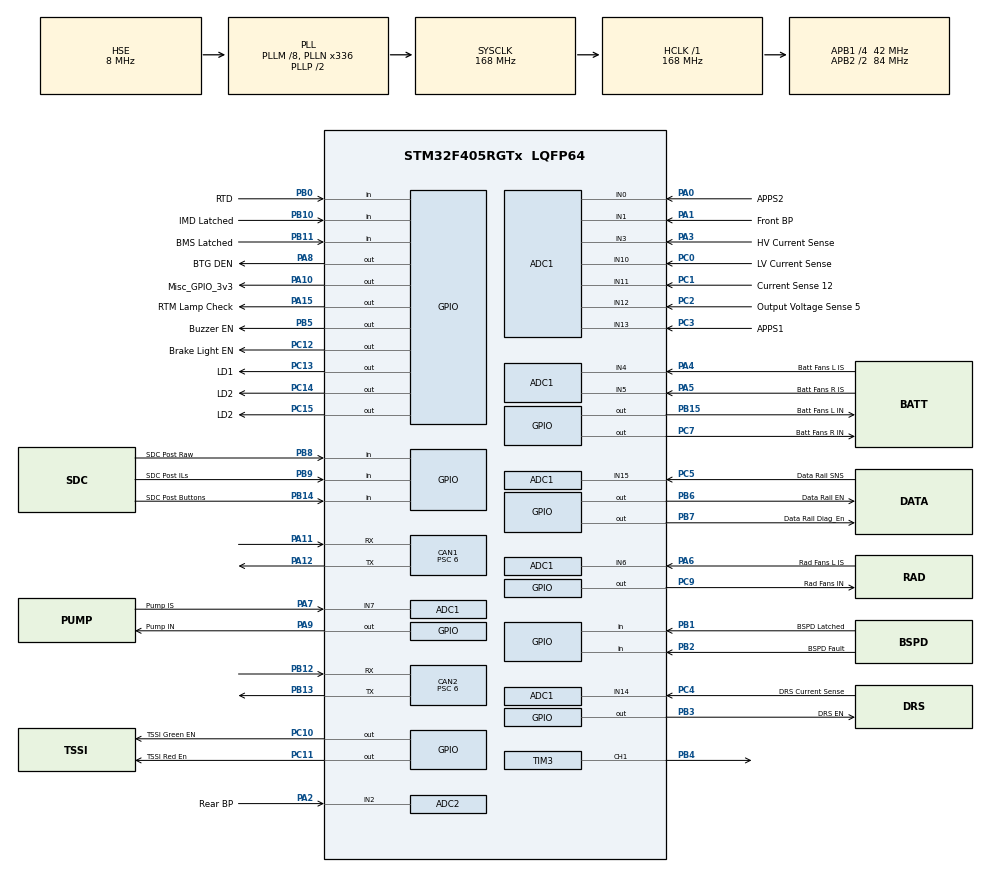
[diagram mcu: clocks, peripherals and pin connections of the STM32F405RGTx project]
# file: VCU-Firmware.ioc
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ADC1.Channel-0\#ChannelRegularConversion=ADC_CHANNEL_0
ADC1.ClockPrescaler=ADC_CLOCK_SYNC_PCLK_DIV6
ADC1.NbrOfConversionFlag=1
ADC1.Rank-0\#ChannelRegularConversion=1
ADC1.SamplingTime-0\#ChannelRegularConversion=ADC_SAMPLETIME_3CYCLES
ADC1.master=1
ADC2.Channel-0\#ChannelRegularConversion=ADC_CHANNEL_2
ADC2.ClockPrescaler=ADC_CLOCK_SYNC_PCLK_DIV6
ADC2.NbrOfConversionFlag=1
ADC2.Rank-0\#ChannelRegularConversion=1
ADC2.SamplingTime-0\#ChannelRegularConversion=ADC_SAMPLETIME_3CYCLES
CAN1.ABOM=ENABLE
CAN1.BS1=CAN_BS1_11TQ
CAN1.BS2=CAN_BS2_2TQ
CAN1.CalculateBaudRate=500000
CAN1.CalculateTimeBit=2000
CAN1.CalculateTimeQuantum=142.85714285714286
CAN1.Mode=CAN_MODE_NORMAL
CAN1.NART=ENABLE
CAN1.Prescaler=6
CAN2.ABOM=ENABLE
CAN2.BS1=CAN_BS1_11TQ
CAN2.BS2=CAN_BS2_2TQ
CAN2.CalculateBaudRate=500000
CAN2.CalculateTimeBit=2000
CAN2.CalculateTimeQuantum=142.85714285714286
CAN2.Mode=CAN_MODE_NORMAL
CAN2.NART=ENABLE
CAN2.Prescaler=6
FREERTOS.Tasks01=defaultTask,24,128,StartDefaultTask,Default,NULL,Dynamic,NULL,NULL;IOManager,24,128,IO_Manager_Task,As external,NULL,Static,IOManagerBuffer,IOManagerControlBlock;CTRLCANManager,24,128,CTRL_CAN_Manager_Task,As external,NULL,Static,CANManagerBuffer,CANManagerControlBlock;DAQCANManager,24,128,DAQ_CAN_Manager_Task,As external,NULL,Static,DAQCANManagerBuffer,DAQCANManagerControlBlock;ConfigManager,8,128,Config_Manager_Task,As external,NULL,Static,ConfigManagerBuffer,ConfigManagerControlBlock
Mcu.Family=STM32F4
Mcu.Name=STM32F405RGTx
Mcu.Package=LQFP64
NVIC.CAN1_RX0_IRQn=true\:5\:0\:false\:false\:true\:true\:true\:true\:true
NVIC.CAN1_RX1_IRQn=true\:5\:0\:false\:false\:true\:true\:true\:true\:true
NVIC.CAN2_RX0_IRQn=true\:5\:0\:false\:false\:true\:true\:true\:true\:true
NVIC.CAN2_RX1_IRQn=true\:5\:0\:false\:false\:true\:true\:true\:true\:true
NVIC.PriorityGroup=NVIC_PRIORITYGROUP_4
NVIC.TIM1_UP_TIM10_IRQn=true\:15\:0\:false\:false\:true\:false\:false\:true\:true
NVIC.TimeBase=TIM1_UP_TIM10_IRQn
NVIC.TimeBaseIP=TIM10
PA0-WKUP.GPIO_Label=APPS2
PA0-WKUP.Signal=ADCx_IN0
PA1.GPIO_Label=Front BP
PA1.Signal=ADCx_IN1
PA10.GPIO_Label=Misc_GPIO_3v3
PA10.Signal=GPIO_Output
PA11.Mode=CAN_Activate
PA11.Signal=CAN1_RX
PA12.Mode=CAN_Activate
PA12.Signal=CAN1_TX
PA15.GPIO_Label=RTM Lamp Check
PA15.Signal=GPIO_Output
PA2.GPIO_Label=Rear BP
PA2.Signal=ADCx_IN2
PA3.GPIO_Label=HV Current Sense
PA3.Signal=ADCx_IN3
PA4.GPIO_Label=Batt Fans L IS
PA4.Signal=ADCx_IN4
PA5.GPIO_Label=Batt Fans R IS
PA5.Signal=ADCx_IN5
PA6.GPIO_Label=Rad Fans L IS
PA6.Signal=ADCx_IN6
PA7.GPIO_Label=Pump IS
PA7.Signal=ADCx_IN7
PA8.GPIO_Label=BTG DEN
PA8.Signal=GPIO_Output
PA9.GPIO_Label=Pump IN
PA9.Signal=GPIO_Output
PB0.GPIO_Label=RTD
PB0.GPIO_PuPd=GPIO_PULLUP
PB0.Signal=GPIO_Input
PB1.GPIO_Label=BSPD Latched
PB1.GPIO_PuPd=GPIO_PULLUP
PB1.Signal=GPIO_Input
PB10.GPIO_Label=IMD Latched
PB10.GPIO_PuPd=GPIO_PULLUP
PB10.Signal=GPIO_Input
PB11.GPIO_Label=BMS Latched
PB11.GPIO_PuPd=GPIO_PULLUP
PB11.Signal=GPIO_Input
PB12.Mode=CAN_Activate
PB12.Signal=CAN2_RX
PB13.Mode=CAN_Activate
PB13.Signal=CAN2_TX
PB14.GPIO_Label=SDC Post Buttons
PB14.GPIO_PuPd=GPIO_PULLUP
PB14.Signal=GPIO_Input
PB15.GPIO_Label=Batt Fans L IN
PB15.Signal=GPIO_Output
PB2.GPIO_Label=BSPD Fault
PB2.GPIO_PuPd=GPIO_PULLUP
PB2.Signal=GPIO_Input
PB3.GPIO_Label=DRS EN
PB3.Signal=GPIO_Output
PB4.Signal=S_TIM3_CH1
PB5.GPIO_Label=Buzzer EN
PB5.Signal=GPIO_Output
PB6.GPIO_Label=Data Rail EN
PB6.Signal=GPIO_Output
PB7.GPIO_Label=Data Rail Diag_En
PB7.Signal=GPIO_Output
PB8.GPIO_Label=SDC Post Raw
PB8.GPIO_PuPd=GPIO_PULLUP
PB8.Signal=GPIO_Input
PB9.GPIO_Label=SDC Post ILs
PB9.GPIO_PuPd=GPIO_PULLUP
PB9.Signal=GPIO_Input
PC0.GPIO_Label=LV Current Sense
PC0.Signal=ADCx_IN10
PC1.GPIO_Label=Current Sense 12
PC1.Signal=ADCx_IN11
PC10.GPIO_Label=TSSI Green EN
PC10.Signal=GPIO_Output
PC11.GPIO_Label=TSSI Red En
PC11.Signal=GPIO_Output
PC12.GPIO_Label=Brake Light EN
PC12.Signal=GPIO_Output
PC13-ANTI_TAMP.GPIO_Label=LD1
PC13-ANTI_TAMP.Signal=GPIO_Output
PC14-OSC32_IN.GPIO_Label=LD2
PC14-OSC32_IN.GPIO_ModeDefaultOutputPP=GPIO_MODE_OUTPUT_OD
PC14-OSC32_IN.GPIO_PuPd=GPIO_NOPULL
PC14-OSC32_IN.Signal=GPIO_Output
PC15-OSC32_OUT.GPIO_Label=LD2
PC15-OSC32_OUT.Signal=GPIO_Output
PC2.GPIO_Label=Output Voltage Sense 5
PC2.Signal=ADCx_IN12
PC3.GPIO_Label=APPS1
PC3.Signal=ADCx_IN13
PC4.GPIO_Label=DRS Current Sense
PC4.Signal=ADCx_IN14
PC5.GPIO_Label=Data Rail SNS
PC5.Signal=ADCx_IN15
PC7.GPIO_Label=Batt Fans R IN
PC7.Signal=GPIO_Output
PC9.GPIO_Label=Rad Fans IN
PC9.Signal=GPIO_Output
PH0-OSC_IN.Mode=HSE-External-Oscillator
PH0-OSC_IN.Signal=RCC_OSC_IN
PH1-OSC_OUT.Mode=HSE-External-Oscillator
PH1-OSC_OUT.Signal=RCC_OSC_OUT
ProjectManager.HeapSize=0x200
ProjectManager.StackSize=0x400
ProjectManager.TargetToolchain=Makefile
RCC.48MHZClocksFreq_Value=84000000
RCC.AHBFreq_Value=168000000
RCC.APB1CLKDivider=RCC_HCLK_DIV4
RCC.APB1Freq_Value=42000000
RCC.APB1TimFreq_Value=84000000
RCC.APB2CLKDivider=RCC_HCLK_DIV2
RCC.APB2Freq_Value=84000000
RCC.APB2TimFreq_Value=168000000
RCC.CortexFreq_Value=168000000
RCC.HCLKFreq_Value=168000000
RCC.HSE_VALUE=8000000
RCC.HSI_VALUE=16000000
RCC.LSE_VALUE=32768
RCC.PLLM=8
RCC.PLLN=336
RCC.PLLSourceVirtual=RCC_PLLSOURCE_HSE
RCC.SYSCLKFreq_VALUE=168000000
RCC.SYSCLKSource=RCC_SYSCLKSOURCE_PLLCLK
RCC.VCOOutputFreq_Value=336000000
SH.ADCx_IN0.0=ADC1_IN0,IN0
SH.ADCx_IN1.0=ADC1_IN1,IN1
SH.ADCx_IN10.0=ADC1_IN10,IN10
SH.ADCx_IN11.0=ADC1_IN11,IN11
SH.ADCx_IN12.0=ADC1_IN12,IN12
SH.ADCx_IN13.0=ADC1_IN13,IN13
SH.ADCx_IN14.0=ADC1_IN14,IN14
SH.ADCx_IN15.0=ADC1_IN15,IN15
SH.ADCx_IN2.0=ADC2_IN2,IN2
SH.ADCx_IN3.0=ADC1_IN3,IN3
SH.ADCx_IN4.0=ADC1_IN4,IN4
SH.ADCx_IN5.0=ADC1_IN5,IN5
SH.ADCx_IN6.0=ADC1_IN6,IN6
SH.ADCx_IN7.0=ADC1_IN7,IN7
SH.S_TIM3_CH1.0=TIM3_CH1,PWM Generation1 CH1
TIM3.AutoReloadPreload=TIM_AUTORELOAD_PRELOAD_ENABLE
TIM3.Channel-PWM\ Generation1\ CH1=TIM_CHANNEL_1
TIM3.Period=8399
VP_FREERTOS_VS_CMSIS_V2.Mode=CMSIS_V2
VP_SYS_VS_tim10.Mode=TIM10
VP_TIM3_VS_ClockSourceINT.Mode=Internal
board=custom

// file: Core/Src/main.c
/* USER CODE BEGIN Header */
/**
  ******************************************************************************
  * @file           : main.c
  * @brief          : Main program body
  ******************************************************************************
  * @attention
  *
  * Copyright (c) 2026 STMicroelectronics.
  * All rights reserved.
  *
  * This software is licensed under terms that can be found in the LICENSE file
  * in the root directory of this software component.
  * If no LICENSE file comes with this software, it is provided AS-IS.
  *
  ******************************************************************************
  */
/* USER CODE END Header */
#include "main.h"
#include "cmsis_os.h"

/* USER CODE BEGIN Includes */

#include <string.h>
#include "managers/can_manager.h"
#include "managers/config_manager.h"
#include "managers/io_manager.h"

/* USER CODE END Includes */

typedef StaticTask_t osStaticThreadDef_t;

ADC_HandleTypeDef hadc1;
ADC_HandleTypeDef hadc2;

CAN_HandleTypeDef hcan1;
CAN_HandleTypeDef hcan2;

TIM_HandleTypeDef htim3;

/* Definitions for defaultTask */
osThreadId_t defaultTaskHandle;
const osThreadAttr_t defaultTask_attributes = {
  .name = "defaultTask",
  .stack_size = 128 * 4,
  .priority = (osPriority_t) osPriorityNormal,
};
/* Definitions for IOManager */
osThreadId_t IOManagerHandle;
uint32_t IOManagerBuffer[ 128 ];
osStaticThreadDef_t IOManagerControlBlock;
const osThreadAttr_t IOManager_attributes = {
  .name = "IOManager",
  .cb_mem = &IOManagerControlBlock,
  .cb_size = sizeof(IOManagerControlBlock),
  .stack_mem = &IOManagerBuffer[0],
  .stack_size = sizeof(IOManagerBuffer),
  .priority = (osPriority_t) osPriorityNormal,
};
/* Definitions for CTRLCANManager */
osThreadId_t CTRLCANManagerHandle;
uint32_t CANManagerBuffer[ 128 ];
osStaticThreadDef_t CANManagerControlBlock;
const osThreadAttr_t CTRLCANManager_attributes = {
  .name = "CTRLCANManager",
  .cb_mem = &CANManagerControlBlock,
  .cb_size = sizeof(CANManagerControlBlock),
  .stack_mem = &CANManagerBuffer[0],
  .stack_size = sizeof(CANManagerBuffer),
  .priority = (osPriority_t) osPriorityNormal,
};
/* Definitions for DAQCANManager */
osThreadId_t DAQCANManagerHandle;
uint32_t DAQCANManagerBuffer[ 128 ];
osStaticThreadDef_t DAQCANManagerControlBlock;
const osThreadAttr_t DAQCANManager_attributes = {
  .name = "DAQCANManager",
  .cb_mem = &DAQCANManagerControlBlock,
  .cb_size = sizeof(DAQCANManagerControlBlock),
  .stack_mem = &DAQCANManagerBuffer[0],
  .stack_size = sizeof(DAQCANManagerBuffer),
  .priority = (osPriority_t) osPriorityNormal,
};
/* Definitions for ConfigManager */
osThreadId_t ConfigManagerHandle;
uint32_t ConfigManagerBuffer[ 128 ];
osStaticThreadDef_t ConfigManagerControlBlock;
const osThreadAttr_t ConfigManager_attributes = {
  .name = "ConfigManager",
  .cb_mem = &ConfigManagerControlBlock,
  .cb_size = sizeof(ConfigManagerControlBlock),
  .stack_mem = &ConfigManagerBuffer[0],
  .stack_size = sizeof(ConfigManagerBuffer),
  .priority = (osPriority_t) osPriorityLow,
};

void SystemClock_Config(void);
static void MX_GPIO_Init(void);
static void MX_ADC1_Init(void);
static void MX_CAN1_Init(void);
static void MX_CAN2_Init(void);
static void MX_ADC2_Init(void);
static void MX_TIM3_Init(void);
void StartDefaultTask(void *argument);
extern void IO_Manager_Task(void *argument);
extern void CTRL_CAN_Manager_Task(void *argument);
extern void DAQ_CAN_Manager_Task(void *argument);
extern void Config_Manager_Task(void *argument);

int main(void)
{

  /* MCU Configuration--------------------------------------------------------*/

  /* Reset of all peripherals, Initializes the Flash interface and the Systick. */
  HAL_Init();

  /* Configure the system clock */
  SystemClock_Config();

  /* Initialize all configured peripherals */
  MX_GPIO_Init();
  MX_ADC1_Init();
  MX_CAN1_Init();
  MX_CAN2_Init();
  MX_ADC2_Init();
  MX_TIM3_Init();

  /* Init scheduler */
  osKernelInitialize();

  /* Create the thread(s) */
  /* creation of defaultTask */
  defaultTaskHandle = osThreadNew(StartDefaultTask, NULL, &defaultTask_attributes);

  /* creation of IOManager */
  IOManagerHandle = osThreadNew(IO_Manager_Task, NULL, &IOManager_attributes);

  /* creation of CTRLCANManager */
  CTRLCANManagerHandle = osThreadNew(CTRL_CAN_Manager_Task, NULL, &CTRLCANManager_attributes);

  /* creation of DAQCANManager */
  DAQCANManagerHandle = osThreadNew(DAQ_CAN_Manager_Task, NULL, &DAQCANManager_attributes);

  /* creation of ConfigManager */
  ConfigManagerHandle = osThreadNew(Config_Manager_Task, NULL, &ConfigManager_attributes);

  /* USER CODE BEGIN RTOS_THREADS */
  if (CTRL_CAN_ManagerInit() != HAL_OK) {
    Error_Handler();
  }
  if (DAQ_CAN_ManagerInit() != HAL_OK) {
    Error_Handler();
  }
  if (IO_Manager_Init() != HAL_OK) {
    Error_Handler();
  }
  if (Config_Manager_Init() != HAL_OK) {
    Error_Handler();
  }
  /* USER CODE END RTOS_THREADS */

  /* Start scheduler */
  osKernelStart();

  /* We should never get here as control is now taken by the scheduler */

  /* Infinite loop */
  while (1)
  {

  }
}

void SystemClock_Config(void)
{
  RCC_OscInitTypeDef RCC_OscInitStruct = {0};
  RCC_ClkInitTypeDef RCC_ClkInitStruct = {0};

  /** Configure the main internal regulator output voltage
  */
  __HAL_RCC_PWR_CLK_ENABLE();
  __HAL_PWR_VOLTAGESCALING_CONFIG(PWR_REGULATOR_VOLTAGE_SCALE1);

  /** Initializes the RCC Oscillators according to the specified parameters
  * in the RCC_OscInitTypeDef structure.
  */
  RCC_OscInitStruct.OscillatorType = RCC_OSCILLATORTYPE_HSE;
  RCC_OscInitStruct.HSEState = RCC_HSE_ON;
  RCC_OscInitStruct.PLL.PLLState = RCC_PLL_ON;
  RCC_OscInitStruct.PLL.PLLSource = RCC_PLLSOURCE_HSE;
  RCC_OscInitStruct.PLL.PLLM = 8;
  RCC_OscInitStruct.PLL.PLLN = 336;
  RCC_OscInitStruct.PLL.PLLP = RCC_PLLP_DIV2;
  RCC_OscInitStruct.PLL.PLLQ = 4;
  if (HAL_RCC_OscConfig(&RCC_OscInitStruct) != HAL_OK)
  {
    Error_Handler();
  }

  /** Initializes the CPU, AHB and APB buses clocks
  */
  RCC_ClkInitStruct.ClockType = RCC_CLOCKTYPE_HCLK|RCC_CLOCKTYPE_SYSCLK
                              |RCC_CLOCKTYPE_PCLK1|RCC_CLOCKTYPE_PCLK2;
  RCC_ClkInitStruct.SYSCLKSource = RCC_SYSCLKSOURCE_PLLCLK;
  RCC_ClkInitStruct.AHBCLKDivider = RCC_SYSCLK_DIV1;
  RCC_ClkInitStruct.APB1CLKDivider = RCC_HCLK_DIV4;
  RCC_ClkInitStruct.APB2CLKDivider = RCC_HCLK_DIV2;

  if (HAL_RCC_ClockConfig(&RCC_ClkInitStruct, FLASH_LATENCY_5) != HAL_OK)
  {
    Error_Handler();
  }
}

static void MX_ADC1_Init(void)
{

  ADC_ChannelConfTypeDef sConfig = {0};

  /** Configure the global features of the ADC (Clock, Resolution, Data Alignment and number of conversion)
  */
  hadc1.Instance = ADC1;
  hadc1.Init.ClockPrescaler = ADC_CLOCK_SYNC_PCLK_DIV6;
  hadc1.Init.Resolution = ADC_RESOLUTION_12B;
  hadc1.Init.ScanConvMode = DISABLE;
  hadc1.Init.ContinuousConvMode = DISABLE;
  hadc1.Init.DiscontinuousConvMode = DISABLE;
  hadc1.Init.ExternalTrigConvEdge = ADC_EXTERNALTRIGCONVEDGE_NONE;
  hadc1.Init.ExternalTrigConv = ADC_SOFTWARE_START;
  hadc1.Init.DataAlign = ADC_DATAALIGN_RIGHT;
  hadc1.Init.NbrOfConversion = 1;
  hadc1.Init.DMAContinuousRequests = DISABLE;
  hadc1.Init.EOCSelection = ADC_EOC_SINGLE_CONV;
  if (HAL_ADC_Init(&hadc1) != HAL_OK)
  {
    Error_Handler();
  }

  /** Configure for the selected ADC regular channel its corresponding rank in the sequencer and its sample time.
  */
  sConfig.Channel = ADC_CHANNEL_0;
  sConfig.Rank = 1;
  sConfig.SamplingTime = ADC_SAMPLETIME_3CYCLES;
  if (HAL_ADC_ConfigChannel(&hadc1, &sConfig) != HAL_OK)
  {
    Error_Handler();
  }

}

static void MX_ADC2_Init(void)
{

  ADC_ChannelConfTypeDef sConfig = {0};

  /** Configure the global features of the ADC (Clock, Resolution, Data Alignment and number of conversion)
  */
  hadc2.Instance = ADC2;
  hadc2.Init.ClockPrescaler = ADC_CLOCK_SYNC_PCLK_DIV6;
  hadc2.Init.Resolution = ADC_RESOLUTION_12B;
  hadc2.Init.ScanConvMode = DISABLE;
  hadc2.Init.ContinuousConvMode = DISABLE;
  hadc2.Init.DiscontinuousConvMode = DISABLE;
  hadc2.Init.ExternalTrigConvEdge = ADC_EXTERNALTRIGCONVEDGE_NONE;
  hadc2.Init.ExternalTrigConv = ADC_SOFTWARE_START;
  hadc2.Init.DataAlign = ADC_DATAALIGN_RIGHT;
  hadc2.Init.NbrOfConversion = 1;
  hadc2.Init.DMAContinuousRequests = DISABLE;
  hadc2.Init.EOCSelection = ADC_EOC_SINGLE_CONV;
  if (HAL_ADC_Init(&hadc2) != HAL_OK)
  {
    Error_Handler();
  }

  /** Configure for the selected ADC regular channel its corresponding rank in the sequencer and its sample time.
  */
  sConfig.Channel = ADC_CHANNEL_2;
  sConfig.Rank = 1;
  sConfig.SamplingTime = ADC_SAMPLETIME_3CYCLES;
  if (HAL_ADC_ConfigChannel(&hadc2, &sConfig) != HAL_OK)
  {
    Error_Handler();
  }

}

static void MX_CAN1_Init(void)
{

  hcan1.Instance = CAN1;
  hcan1.Init.Prescaler = 6;
  hcan1.Init.Mode = CAN_MODE_NORMAL;
  hcan1.Init.SyncJumpWidth = CAN_SJW_1TQ;
  hcan1.Init.TimeSeg1 = CAN_BS1_11TQ;
  hcan1.Init.TimeSeg2 = CAN_BS2_2TQ;
  hcan1.Init.TimeTriggeredMode = DISABLE;
  hcan1.Init.AutoBusOff = ENABLE;
  hcan1.Init.AutoWakeUp = DISABLE;
  hcan1.Init.AutoRetransmission = ENABLE;
  hcan1.Init.ReceiveFifoLocked = DISABLE;
  hcan1.Init.TransmitFifoPriority = DISABLE;
  if (HAL_CAN_Init(&hcan1) != HAL_OK)
  {
    Error_Handler();
  }

}

static void MX_CAN2_Init(void)
{

  hcan2.Instance = CAN2;
  hcan2.Init.Prescaler = 6;
  hcan2.Init.Mode = CAN_MODE_NORMAL;
  hcan2.Init.SyncJumpWidth = CAN_SJW_1TQ;
  hcan2.Init.TimeSeg1 = CAN_BS1_11TQ;
  hcan2.Init.TimeSeg2 = CAN_BS2_2TQ;
  hcan2.Init.TimeTriggeredMode = DISABLE;
  hcan2.Init.AutoBusOff = ENABLE;
  hcan2.Init.AutoWakeUp = DISABLE;
  hcan2.Init.AutoRetransmission = ENABLE;
  hcan2.Init.ReceiveFifoLocked = DISABLE;
  hcan2.Init.TransmitFifoPriority = DISABLE;
  if (HAL_CAN_Init(&hcan2) != HAL_OK)
  {
    Error_Handler();
  }

}

static void MX_TIM3_Init(void)
{

  TIM_ClockConfigTypeDef sClockSourceConfig = {0};
  TIM_MasterConfigTypeDef sMasterConfig = {0};
  TIM_OC_InitTypeDef sConfigOC = {0};

  htim3.Instance = TIM3;
  htim3.Init.Prescaler = 0;
  htim3.Init.CounterMode = TIM_COUNTERMODE_UP;
  htim3.Init.Period = 8399;
  htim3.Init.ClockDivision = TIM_CLOCKDIVISION_DIV1;
  htim3.Init.AutoReloadPreload = TIM_AUTORELOAD_PRELOAD_ENABLE;
  if (HAL_TIM_Base_Init(&htim3) != HAL_OK)
  {
    Error_Handler();
  }
  sClockSourceConfig.ClockSource = TIM_CLOCKSOURCE_INTERNAL;
  if (HAL_TIM_ConfigClockSource(&htim3, &sClockSourceConfig) != HAL_OK)
  {
    Error_Handler();
  }
  if (HAL_TIM_PWM_Init(&htim3) != HAL_OK)
  {
    Error_Handler();
  }
  sMasterConfig.MasterOutputTrigger = TIM_TRGO_RESET;
  sMasterConfig.MasterSlaveMode = TIM_MASTERSLAVEMODE_DISABLE;
  if (HAL_TIMEx_MasterConfigSynchronization(&htim3, &sMasterConfig) != HAL_OK)
  {
    Error_Handler();
  }
  sConfigOC.OCMode = TIM_OCMODE_PWM1;
  sConfigOC.Pulse = 0;
  sConfigOC.OCPolarity = TIM_OCPOLARITY_HIGH;
  sConfigOC.OCFastMode = TIM_OCFAST_DISABLE;
  if (HAL_TIM_PWM_ConfigChannel(&htim3, &sConfigOC, TIM_CHANNEL_1) != HAL_OK)
  {
    Error_Handler();
  }
  HAL_TIM_MspPostInit(&htim3);

}

static void MX_GPIO_Init(void)
{
  GPIO_InitTypeDef GPIO_InitStruct = {0};

  /* GPIO Ports Clock Enable */
  __HAL_RCC_GPIOC_CLK_ENABLE();
  __HAL_RCC_GPIOH_CLK_ENABLE();
  __HAL_RCC_GPIOA_CLK_ENABLE();
  __HAL_RCC_GPIOB_CLK_ENABLE();

  /*Configure GPIO pin Output Level */
  HAL_GPIO_WritePin(GPIOC, LD1_Pin|LD2_Pin|LD2C15_Pin|Batt_Fans_R_IN_Pin
                          |Rad_Fans_IN_Pin|TSSI_Green_EN_Pin|TSSI_Red_En_Pin|Brake_Light_EN_Pin, GPIO_PIN_RESET);

  /*Configure GPIO pin Output Level */
  HAL_GPIO_WritePin(GPIOB, Batt_Fans_L_IN_Pin|DRS_EN_Pin|Buzzer_EN_Pin|Data_Rail_EN_Pin
                          |Data_Rail_Diag_En_Pin, GPIO_PIN_RESET);

  /*Configure GPIO pin Output Level */
  HAL_GPIO_WritePin(GPIOA, BTG_DEN_Pin|Pump_IN_Pin|Misc_GPIO_3v3_Pin|RTM_Lamp_Check_Pin, GPIO_PIN_RESET);

  /*Configure GPIO pins : LD1_Pin LD2C15_Pin Batt_Fans_R_IN_Pin Rad_Fans_IN_Pin
                           TSSI_Green_EN_Pin TSSI_Red_En_Pin Brake_Light_EN_Pin */
  GPIO_InitStruct.Pin = LD1_Pin|LD2C15_Pin|Batt_Fans_R_IN_Pin|Rad_Fans_IN_Pin
                          |TSSI_Green_EN_Pin|TSSI_Red_En_Pin|Brake_Light_EN_Pin;
  GPIO_InitStruct.Mode = GPIO_MODE_OUTPUT_PP;
  GPIO_InitStruct.Pull = GPIO_NOPULL;
  GPIO_InitStruct.Speed = GPIO_SPEED_FREQ_LOW;
  HAL_GPIO_Init(GPIOC, &GPIO_InitStruct);

  /*Configure GPIO pin : LD2_Pin */
  GPIO_InitStruct.Pin = LD2_Pin;
  GPIO_InitStruct.Mode = GPIO_MODE_OUTPUT_OD;
  GPIO_InitStruct.Pull = GPIO_NOPULL;
  GPIO_InitStruct.Speed = GPIO_SPEED_FREQ_LOW;
  HAL_GPIO_Init(LD2_GPIO_Port, &GPIO_InitStruct);

  /*Configure GPIO pins : RTD_Pin BSPD_Latched_Pin BSPD_Fault_Pin IMD_Latched_Pin
                           BMS_Latched_Pin SDC_Post_Buttons_Pin SDC_Post_Raw_Pin SDC_Post_ILs_Pin */
  GPIO_InitStruct.Pin = RTD_Pin|BSPD_Latched_Pin|BSPD_Fault_Pin|IMD_Latched_Pin
                          |BMS_Latched_Pin|SDC_Post_Buttons_Pin|SDC_Post_Raw_Pin|SDC_Post_ILs_Pin;
  GPIO_InitStruct.Mode = GPIO_MODE_INPUT;
  GPIO_InitStruct.Pull = GPIO_PULLUP;
  HAL_GPIO_Init(GPIOB, &GPIO_InitStruct);

  /*Configure GPIO pins : Batt_Fans_L_IN_Pin DRS_EN_Pin Buzzer_EN_Pin Data_Rail_EN_Pin
                           Data_Rail_Diag_En_Pin */
  GPIO_InitStruct.Pin = Batt_Fans_L_IN_Pin|DRS_EN_Pin|Buzzer_EN_Pin|Data_Rail_EN_Pin
                          |Data_Rail_Diag_En_Pin;
  GPIO_InitStruct.Mode = GPIO_MODE_OUTPUT_PP;
  GPIO_InitStruct.Pull = GPIO_NOPULL;
  GPIO_InitStruct.Speed = GPIO_SPEED_FREQ_LOW;
  HAL_GPIO_Init(GPIOB, &GPIO_InitStruct);

  /*Configure GPIO pins : BTG_DEN_Pin Pump_IN_Pin Misc_GPIO_3v3_Pin RTM_Lamp_Check_Pin */
  GPIO_InitStruct.Pin = BTG_DEN_Pin|Pump_IN_Pin|Misc_GPIO_3v3_Pin|RTM_Lamp_Check_Pin;
  GPIO_InitStruct.Mode = GPIO_MODE_OUTPUT_PP;
  GPIO_InitStruct.Pull = GPIO_NOPULL;
  GPIO_InitStruct.Speed = GPIO_SPEED_FREQ_LOW;
  HAL_GPIO_Init(GPIOA, &GPIO_InitStruct);

}

void StartDefaultTask(void *argument)
{
  for(;;)
  {
    osDelay(1);
  }
}

void HAL_TIM_PeriodElapsedCallback(TIM_HandleTypeDef *htim)
{
  if (htim->Instance == TIM10)
  {
    HAL_IncTick();
  }
}

void Error_Handler(void)
{
  __disable_irq();
  while (1)
  {
  }
}
